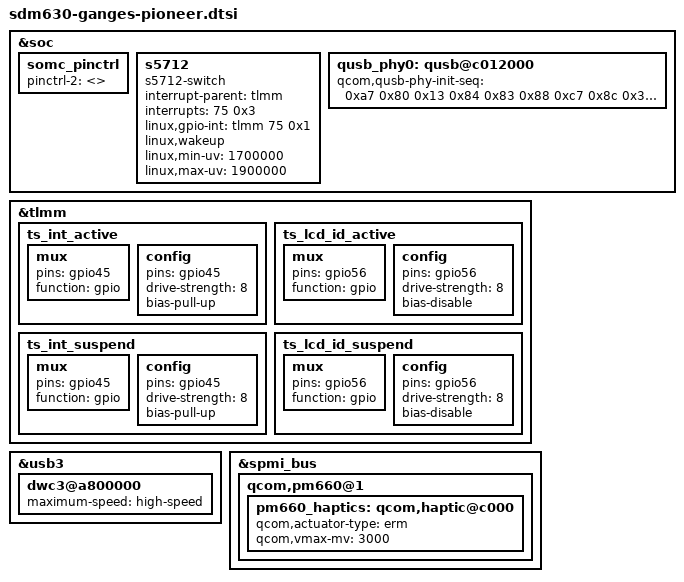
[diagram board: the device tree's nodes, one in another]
/* arch/arm64/boot/dts/somc/sdm630-ganges-pioneer.dtsi
 *
 * This program is free software; you can redistribute it and/or modify
 * it under the terms of the GNU General Public License version 2 and
 * only version 2 as published by the Free Software Foundation.
 *
 * This program is distributed in the hope that it will be useful,
 * but WITHOUT ANY WARRANTY; without even the implied warranty of
 * MERCHANTABILITY or FITNESS FOR A PARTICULAR PURPOSE.  See the
 * GNU General Public License for more details.
*/

#include "sdm630-ganges-common.dtsi"
#include "dsi-panel-pioneer.dtsi"
#include "sdm630-ganges-touch.dtsi"
#include "sdm630-ganges-pioneer-camera-sensor.dtsi"
#include "charger-ganges-pioneer.dtsi"
#include "sdm630-ganges-nfc_pn553.dtsi"

&soc {
	somc_pinctrl: somc_pinctrl {
		/* If variant specific default setting is needed,
		fill pinctrl-2 value in <variant>.dtsi */
		pinctrl-2 = <>;
	};

	s5712 {
		compatible = "s5712-switch";
		interrupt-parent = <&tlmm>;
		interrupts = <75 0x3>;
		//vddio-supply = <&pm660l_l14>;
		linux,gpio-int = <&tlmm 75 0x1>;
		linux,wakeup;
		linux,min-uv = <1700000>;
		linux,max-uv = <1900000>;
	};

	qusb_phy0: qusb@c012000 {
		qcom,qusb-phy-init-seq = <0xa7 0x80
			0x13 0x84
			0x83 0x88
			0xc7 0x8c
			0x30 0x08
			0x79 0x0c
			0x21 0x10
			0x14 0x9c
			0x9f 0x1c
			0x00 0x18>;
	};
};

&tlmm {
/* for Touch pinctrl */
	ts_int_active: ts_int_active {
		mux {
			pins = "gpio45";
			function = "gpio";
		};

		config {
			pins = "gpio45";
			drive-strength = <8>;
			bias-pull-up;
		};
	};

	ts_lcd_id_active: ts_lcd_id_active {
		mux {
			pins = "gpio56";
			function = "gpio";
		};

		config {
			pins = "gpio56";
			drive-strength = <8>;
			bias-disable;
		};
	};

	ts_int_suspend: ts_int_suspend {
		mux {
			pins = "gpio45";
			function = "gpio";
		};

		config {
			pins = "gpio45";
			drive-strength = <8>;
			bias-pull-up;
		};
	};

	ts_lcd_id_suspend: ts_lcd_id_suspend {
		mux {
			pins = "gpio56";
			function = "gpio";
		};

		config {
			pins = "gpio56";
			drive-strength = <8>;
			bias-disable;
		};
	};
};

&usb3 {
	dwc3@a800000 {
		maximum-speed = "high-speed";
	};
};

&spmi_bus {
	qcom,pm660@1 {
		pm660_haptics: qcom,haptic@c000 {
			qcom,actuator-type = "erm";
			qcom,vmax-mv = <3000>;
		};
	};
};
